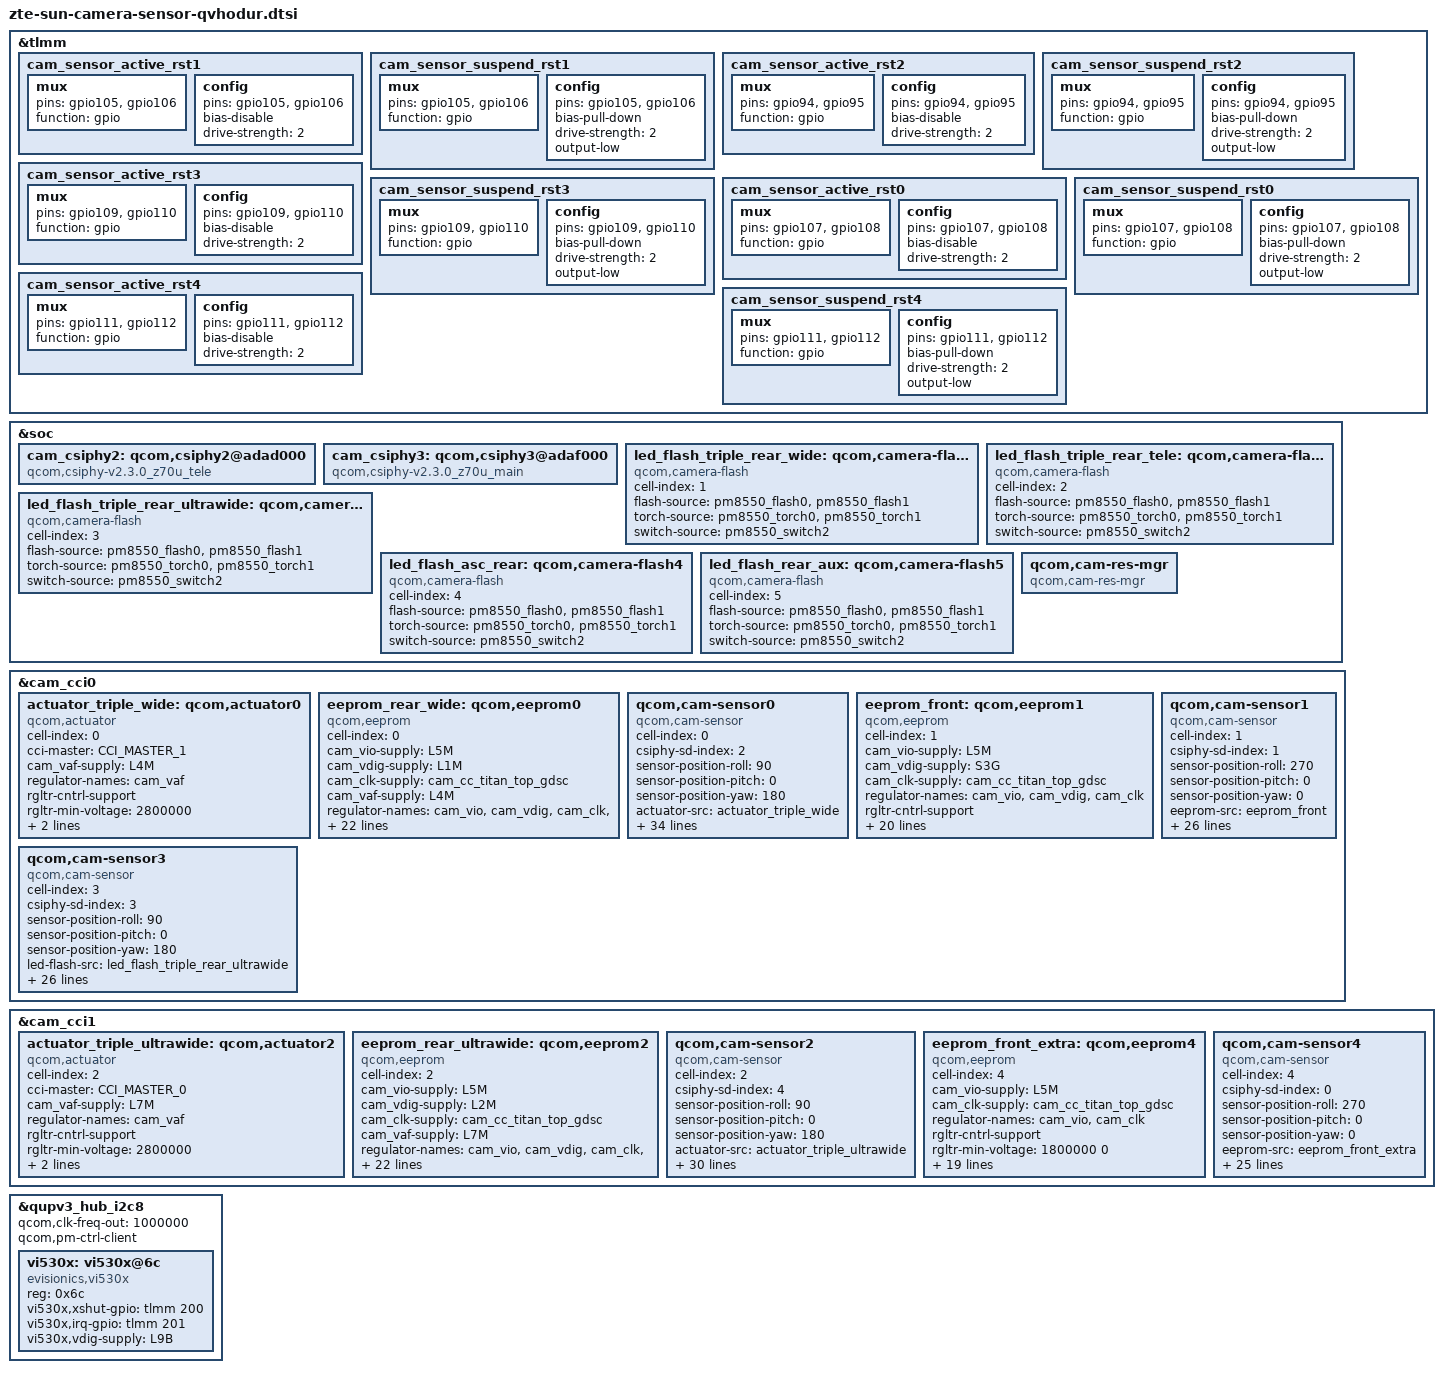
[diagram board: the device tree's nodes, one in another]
#include <dt-bindings/msm-camera.h>
&tlmm {
	cam_sensor_active_rst1: cam_sensor_active_rst1 {
		mux {
			pins = "gpio105", "gpio106";
			function = "gpio";
		};

		config {
			pins = "gpio105", "gpio106";
			bias-disable; /* No PULL */
			drive-strength = <2>; /* 2 MA */
		};
	};

	cam_sensor_suspend_rst1: cam_sensor_suspend_rst1 {
		mux {
			pins = "gpio105", "gpio106";
			function = "gpio";
		};

		config {
			pins = "gpio105", "gpio106";
			bias-pull-down; /* PULL DOWN */
			drive-strength = <2>; /* 2 MA */
			output-low;
		};
	};

	cam_sensor_active_rst2: cam_sensor_active_rst2 {
		mux {
			pins = "gpio94", "gpio95";
			function = "gpio";
		};

		config {
			pins = "gpio94", "gpio95";
			bias-disable; /* No PULL */
			drive-strength = <2>; /* 2 MA */
		};
	};

	cam_sensor_suspend_rst2: cam_sensor_suspend_rst2 {
		mux {
			pins = "gpio94", "gpio95";
			function = "gpio";
		};

		config {
			pins = "gpio94", "gpio95";
			bias-pull-down; /* PULL DOWN */
			drive-strength = <2>; /* 2 MA */
			output-low;
		};
	};

	cam_sensor_active_rst3: cam_sensor_active_rst3 {
		mux {
			pins = "gpio109", "gpio110";
			function = "gpio";
		};

		config {
			pins = "gpio109", "gpio110";
			bias-disable; /* No PULL */
			drive-strength = <2>; /* 2 MA */
		};
	};

	cam_sensor_suspend_rst3: cam_sensor_suspend_rst3 {
		mux {
			pins = "gpio109", "gpio110";
			function = "gpio";
		};

		config {
			pins = "gpio109", "gpio110";
			bias-pull-down; /* PULL DOWN */
			drive-strength = <2>; /* 2 MA */
			output-low;
		};
	};

	cam_sensor_active_rst0: cam_sensor_active_rst0 {
		mux {
			pins = "gpio107", "gpio108";
			function = "gpio";
		};

		config {
			pins = "gpio107", "gpio108";
			bias-disable; /* No PULL */
			drive-strength = <2>; /* 2 MA */
		};
	};

	cam_sensor_suspend_rst0: cam_sensor_suspend_rst0 {
		mux {
			pins = "gpio107", "gpio108";
			function = "gpio";
		};

		config {
			pins = "gpio107", "gpio108";
			bias-pull-down; /* PULL DOWN */
			drive-strength = <2>; /* 2 MA */
			output-low;
		};
	};

	cam_sensor_active_rst4: cam_sensor_active_rst4 {
		mux {
			pins = "gpio111", "gpio112";
			function = "gpio";
		};

		config {
			pins = "gpio111", "gpio112";
			bias-disable; /* No PULL */
			drive-strength = <2>; /* 2 MA */
		};
	};

	cam_sensor_suspend_rst4: cam_sensor_suspend_rst4 {
		mux {
			pins = "gpio111", "gpio112";
			function = "gpio";
		};

		config {
			pins = "gpio111", "gpio112";
			bias-pull-down; /* PULL DOWN */
			drive-strength = <2>; /* 2 MA */
			output-low;
		};
	};

};

&soc {
	cam_csiphy2: qcom,csiphy2@adad000 {
		compatible = "qcom,csiphy-v2.3.0_z70u_tele", "qcom,csiphy";
	};

	cam_csiphy3: qcom,csiphy3@adaf000 {
		compatible = "qcom,csiphy-v2.3.0_z70u_main", "qcom,csiphy";
	};

	led_flash_triple_rear_wide: qcom,camera-flash1 {
		cell-index = <1>;
		compatible = "qcom,camera-flash";
		flash-source = <&pm8550_flash0 &pm8550_flash1>;
		torch-source = <&pm8550_torch0 &pm8550_torch1>;
		switch-source = <&pm8550_switch2>;
		status = "ok";
	};

	led_flash_triple_rear_tele: qcom,camera-flash2 {
		cell-index = <2>;
		compatible = "qcom,camera-flash";
		flash-source = <&pm8550_flash0 &pm8550_flash1>;
		torch-source = <&pm8550_torch0 &pm8550_torch1>;
		switch-source = <&pm8550_switch2>;
		status = "ok";
	};

	led_flash_triple_rear_ultrawide: qcom,camera-flash3 {
		cell-index = <3>;
		compatible = "qcom,camera-flash";
		flash-source = <&pm8550_flash0 &pm8550_flash1>;
		torch-source = <&pm8550_torch0 &pm8550_torch1>;
		switch-source = <&pm8550_switch2>;
		status = "ok";
	};

	led_flash_asc_rear: qcom,camera-flash4 {
		cell-index = <4>;
		compatible = "qcom,camera-flash";
		flash-source = <&pm8550_flash0 &pm8550_flash1>;
		torch-source = <&pm8550_torch0 &pm8550_torch1>;
		switch-source = <&pm8550_switch2>;
		status = "ok";
	};

	led_flash_rear_aux: qcom,camera-flash5 {
		cell-index = <5>;
		compatible = "qcom,camera-flash";
		flash-source = <&pm8550_flash0 &pm8550_flash1>;
		torch-source = <&pm8550_torch0 &pm8550_torch1>;
		switch-source = <&pm8550_switch2>;
		status = "ok";
	};

	qcom,cam-res-mgr {
		compatible = "qcom,cam-res-mgr";
		status = "ok";
	};
};

&cam_cci0 {
	actuator_triple_wide: qcom,actuator0 {
		cell-index = <0>;
		compatible = "qcom,actuator";
		cci-master = <CCI_MASTER_1>;
		cam_vaf-supply = <&L4M>;
		regulator-names = "cam_vaf";
		rgltr-cntrl-support;
		rgltr-min-voltage = <2800000>;
		rgltr-max-voltage = <2800000>;
		rgltr-load-current = <67700>;
	};

	eeprom_rear_wide: qcom,eeprom0 {
		cell-index = <0>;
		compatible = "qcom,eeprom";
		cam_vio-supply = <&L5M>;
		cam_vdig-supply = <&L1M>;
		cam_clk-supply = <&cam_cc_titan_top_gdsc>;
		cam_vaf-supply = <&L4M>;
		regulator-names = "cam_vio", "cam_vdig", "cam_clk", "cam_vaf";
		rgltr-cntrl-support;
		rgltr-min-voltage = <1800000 1104000 0 2800000>;
		rgltr-max-voltage = <1800000 1104000 0 2800000>;
		rgltr-load-current = <155000 680000 0 67700>;
		gpio-no-mux = <0>;
		pinctrl-names = "cam_default", "cam_suspend";
		pinctrl-0 = <&cam_sensor_mclk1_active
				 &cam_sensor_active_rst1>;
		pinctrl-1 = <&cam_sensor_mclk1_suspend
				 &cam_sensor_suspend_rst1>;
		gpios = <&tlmm 90 0>,
			<&tlmm 105 0>,
			<&tlmm 106 0>;
		gpio-reset = <1>;
		gpio-custom1 = <2>;
		gpio-req-tbl-num = <0 1 2>;
		gpio-req-tbl-flags = <1 0 0>;
		gpio-req-tbl-label = "CAMIF_MCLK1",
					"CAM_RESET1",
					"CAM_VANA1";
		cci-master = <CCI_MASTER_1>;
		clocks = <&cambistmclkcc CAM_BIST_MCLK_CC_MCLK1_CLK>;
		clock-names = "cam_clk";
		clock-cntl-level = "nominal";
		clock-rates = <24000000>;
		status = "ok";
	};

	qcom,cam-sensor0 {
		cell-index = <0>;
		compatible = "qcom,cam-sensor";
		csiphy-sd-index = <2>;
		sensor-position-roll = <90>;
		sensor-position-pitch = <0>;
		sensor-position-yaw = <180>;
		actuator-src = <&actuator_triple_wide>;
		led-flash-src = <&led_flash_triple_rear_wide>;
		eeprom-src = <&eeprom_rear_wide>;
		cam_vio-supply = <&L5M>;
		cam_vdig-supply = <&L1M>;
		cam_clk-supply = <&cam_cc_titan_top_gdsc>;
		cam_vaf-supply = <&L4M>;
		cam_v_custom1-supply = <&L6M>;
		regulator-names = "cam_vio", "cam_vdig", "cam_clk", "cam_vaf", "cam_v_custom1";
		rgltr-cntrl-support;
		rgltr-min-voltage = <1800000 1104000 0 2800000 2800000>;
		rgltr-max-voltage = <1800000 1104000 0 2800000 2800000>;
		rgltr-load-current = <155000 680000 0 67700 67700>;
		gpio-no-mux = <0>;
		pinctrl-names = "cam_default", "cam_suspend";
		pinctrl-0 = <&cam_sensor_mclk1_active
				 &cam_sensor_active_rst1>;
		pinctrl-1 = <&cam_sensor_mclk1_suspend
				 &cam_sensor_suspend_rst1>;
		gpios = <&tlmm 90 0>,
			<&tlmm 105 0>,
			<&tlmm 106 0>;
		gpio-reset = <1>;
		gpio-custom1 = <2>;
		gpio-req-tbl-num = <0 1 2>;
		gpio-req-tbl-flags = <1 0 0>;
		gpio-req-tbl-label = "CAMIF_MCLK1",
					"CAM_RESET1",
					"CAM_VANA1";
		cci-master = <CCI_MASTER_1>;
		clocks = <&cambistmclkcc CAM_BIST_MCLK_CC_MCLK1_CLK>;
		clock-names = "cam_clk";
		clock-cntl-level = "nominal";
		clock-rates = <24000000>;
		status = "ok";
		zte-tof-enable;
	};

	eeprom_front: qcom,eeprom1 {
		cell-index = <1>;
		compatible = "qcom,eeprom";
		cam_vio-supply = <&L5M>;
		cam_vdig-supply = <&S3G>;
		cam_clk-supply = <&cam_cc_titan_top_gdsc>;
		regulator-names = "cam_vio", "cam_vdig", "cam_clk";
		rgltr-cntrl-support;
		rgltr-min-voltage = <1800000 1856000 0>;
		rgltr-max-voltage = <1800000 2000000 0>;
		rgltr-load-current = <4000 4000 0>;
		gpio-no-mux = <0>;
		pinctrl-names = "cam_default", "cam_suspend";
		pinctrl-0 = <&cam_sensor_mclk0_active
				 &cam_sensor_active_rst0>;
		pinctrl-1 = <&cam_sensor_mclk0_suspend
				 &cam_sensor_suspend_rst0>;
		gpios = <&tlmm 89 0>,
			<&tlmm 107 0>,
			<&tlmm 108 0>;
		gpio-reset = <1>;
		gpio-custom1 = <2>;
		gpio-req-tbl-num = <0 1 2>;
		gpio-req-tbl-flags = <1 0 0>;
		gpio-req-tbl-label = "CAMIF_MCLK0",
					"CAM_RESET0",
					"CAM_VANA0";
		cci-master = <CCI_MASTER_0>;
		clocks = <&cambistmclkcc CAM_BIST_MCLK_CC_MCLK0_CLK>;
		clock-names = "cam_clk";
		clock-cntl-level = "nominal";
		clock-rates = <24000000>;
		status = "ok";
	};

	qcom,cam-sensor1 {
		cell-index = <1>;
		compatible = "qcom,cam-sensor";
		csiphy-sd-index = <1>;
		sensor-position-roll = <270>;
		sensor-position-pitch = <0>;
		sensor-position-yaw = <0>;
		eeprom-src = <&eeprom_front>;
		cam_vio-supply = <&L5M>;
		cam_vdig-supply = <&S3G>;
		cam_clk-supply = <&cam_cc_titan_top_gdsc>;
		regulator-names = "cam_vio", "cam_vdig", "cam_clk";
		rgltr-cntrl-support;
		rgltr-min-voltage = <1800000 1856000 0>;
		rgltr-max-voltage = <1800000 2000000 0>;
		rgltr-load-current = <4000 4000 0>;
		gpio-no-mux = <0>;
		pinctrl-names = "cam_default", "cam_suspend";
		pinctrl-0 = <&cam_sensor_mclk0_active
				 &cam_sensor_active_rst0>;
		pinctrl-1 = <&cam_sensor_mclk0_suspend
				 &cam_sensor_suspend_rst0>;
		gpios = <&tlmm 89 0>,
			<&tlmm 107 0>,
			<&tlmm 108 0>;
		gpio-reset = <1>;
		gpio-custom1 = <2>;
		gpio-req-tbl-num = <0 1 2>;
		gpio-req-tbl-flags = <1 0 0>;
		gpio-req-tbl-label = "CAMIF_MCLK0",
					"CAM_RESET0",
					"CAM_VANA0";
		cci-master = <CCI_MASTER_0>;
		clocks = <&cambistmclkcc CAM_BIST_MCLK_CC_MCLK0_CLK>;
		clock-names = "cam_clk";
		clock-cntl-level = "nominal";
		clock-rates = <24000000>;
		status = "ok";
		zte-tof-enable;
	};

	qcom,cam-sensor3 {
		cell-index = <3>;
		compatible = "qcom,cam-sensor";
		csiphy-sd-index = <3>;
		sensor-position-roll = <90>;
		sensor-position-pitch = <0>;
		sensor-position-yaw = <180>;
		led-flash-src = <&led_flash_triple_rear_ultrawide>;
		cam_vio-supply = <&L5M>;
		cam_vdig-supply = <&S3G>;
		cam_clk-supply = <&cam_cc_titan_top_gdsc>;
		regulator-names = "cam_vio", "cam_vdig", "cam_clk";
		rgltr-cntrl-support;
		rgltr-min-voltage = <1800000 1856000 0>;
		rgltr-max-voltage = <1800000 2000000 0>;
		rgltr-load-current = <4000 4000 0>;
		gpio-no-mux = <0>;
		pinctrl-names = "cam_default", "cam_suspend";
		pinctrl-0 = <&cam_sensor_mclk3_active
				 &cam_sensor_active_rst3>;
		pinctrl-1 = <&cam_sensor_mclk3_suspend
				 &cam_sensor_suspend_rst3>;
		gpios = <&tlmm 92 0>,
			<&tlmm 109 0>,
			<&tlmm 110 0>;
		gpio-reset = <1>;
		gpio-custom1 = <2>;
		gpio-req-tbl-num = <0 1 2>;
		gpio-req-tbl-flags = <1 0 0>;
		gpio-req-tbl-label = "CAMIF_MCLK3",
					"CAM_RESET3",
					"CAM_VANA3";
		cci-master = <CCI_MASTER_0>;
		clocks = <&cambistmclkcc CAM_BIST_MCLK_CC_MCLK3_CLK>;
		clock-names = "cam_clk";
		clock-cntl-level = "nominal";
		clock-rates = <24000000>;
		status = "ok";
		zte-tof-enable;
	};

};

&cam_cci1 {
	actuator_triple_ultrawide: qcom,actuator2 {
		cell-index = <2>;
		compatible = "qcom,actuator";
		cci-master = <CCI_MASTER_0>;
		cam_vaf-supply = <&L7M>;
		regulator-names = "cam_vaf";
		rgltr-cntrl-support;
		rgltr-min-voltage = <2800000>;
		rgltr-max-voltage = <2800000>;
		rgltr-load-current = <119000>;
	};

	eeprom_rear_ultrawide: qcom,eeprom2 {
		cell-index = <2>;
		compatible = "qcom,eeprom";
		cam_vio-supply = <&L5M>;
		cam_vdig-supply = <&L2M>;
		cam_clk-supply = <&cam_cc_titan_top_gdsc>;
		cam_vaf-supply = <&L7M>;
		regulator-names = "cam_vio", "cam_vdig", "cam_clk", "cam_vaf";
		rgltr-cntrl-support;
		rgltr-min-voltage = <1800000 1100000 0 2800000>;
		rgltr-max-voltage = <1800000 1100000 0 2800000>;
		rgltr-load-current = <4000 155000 0 119000>;
		gpio-no-mux = <0>;
		pinctrl-names = "cam_default", "cam_suspend";
		pinctrl-0 = <&cam_sensor_mclk2_active
				 &cam_sensor_active_rst2>;
		pinctrl-1 = <&cam_sensor_mclk2_suspend
				 &cam_sensor_suspend_rst2>;
		gpios = <&tlmm 91 0>,
			<&tlmm 94 0>,
			<&tlmm 95 0>;
		gpio-reset = <1>;
		gpio-custom1 = <2>;
		gpio-req-tbl-num = <0 1 2>;
		gpio-req-tbl-flags = <1 0 0>;
		gpio-req-tbl-label = "CAMIF_MCLK2",
					"CAM_RESET2",
					"CAM_VANA2";
		cci-master = <CCI_MASTER_0>;
		clocks = <&cambistmclkcc CAM_BIST_MCLK_CC_MCLK2_CLK>;
		clock-names = "cam_clk";
		clock-cntl-level = "nominal";
		clock-rates = <24000000>;
		status = "ok";
	};

	qcom,cam-sensor2 {
		cell-index = <2>;
		compatible = "qcom,cam-sensor";
		csiphy-sd-index = <4>;
		sensor-position-roll = <90>;
		sensor-position-pitch = <0>;
		sensor-position-yaw = <180>;
		actuator-src = <&actuator_triple_ultrawide>;
		led-flash-src = <&led_flash_triple_rear_ultrawide>;
		eeprom-src = <&eeprom_rear_ultrawide>;
		cam_vio-supply = <&L5M>;
		cam_vdig-supply = <&L2M>;
		cam_clk-supply = <&cam_cc_titan_top_gdsc>;
		cam_vaf-supply = <&L7M>;
		regulator-names = "cam_vio", "cam_vdig", "cam_clk", "cam_vaf";
		rgltr-cntrl-support;
		rgltr-min-voltage = <1800000 1100000 0 2800000>;
		rgltr-max-voltage = <1800000 1100000 0 2800000>;
		rgltr-load-current = <4000 155000 0 119000>;
		gpio-no-mux = <0>;
		pinctrl-names = "cam_default", "cam_suspend";
		pinctrl-0 = <&cam_sensor_mclk2_active
				 &cam_sensor_active_rst2>;
		pinctrl-1 = <&cam_sensor_mclk2_suspend
				 &cam_sensor_suspend_rst2>;
		gpios = <&tlmm 91 0>,
			<&tlmm 94 0>,
			<&tlmm 95 0>;
		gpio-reset = <1>;
		gpio-custom1 = <2>;
		gpio-req-tbl-num = <0 1 2>;
		gpio-req-tbl-flags = <1 0 0>;
		gpio-req-tbl-label = "CAMIF_MCLK2",
					"CAM_RESET2",
					"CAM_VANA2";
		cci-master = <CCI_MASTER_0>;
		clocks = <&cambistmclkcc CAM_BIST_MCLK_CC_MCLK2_CLK>;
		clock-names = "cam_clk";
		clock-cntl-level = "nominal";
		clock-rates = <24000000>;
		status = "ok";
		zte-tof-enable;
	};

	eeprom_front_extra: qcom,eeprom4 {
		cell-index = <4>;
		compatible = "qcom,eeprom";
		cam_vio-supply = <&L5M>;
		cam_clk-supply = <&cam_cc_titan_top_gdsc>;
		regulator-names = "cam_vio", "cam_clk";
		rgltr-cntrl-support;
		rgltr-min-voltage = <1800000 0>;
		rgltr-max-voltage = <1800000 0>;
		rgltr-load-current = <4000 0>;
		gpio-no-mux = <0>;
		pinctrl-names = "cam_default", "cam_suspend";
		pinctrl-0 = <&cam_sensor_mclk4_active
				 &cam_sensor_active_rst4>;
		pinctrl-1 = <&cam_sensor_mclk4_suspend
				 &cam_sensor_suspend_rst4>;
		gpios = <&tlmm 93 0>,
			<&tlmm 111 0>,
			<&tlmm 112 0>;
		gpio-reset = <1>;
		gpio-custom1 = <2>;
		gpio-req-tbl-num = <0 1 2>;
		gpio-req-tbl-flags = <1 0 0>;
		gpio-req-tbl-label = "CAMIF_MCLK4",
					"CAM_RESET4",
					"CAM_VANA4";
		cci-master = <CCI_MASTER_0>;
		clocks = <&cambistmclkcc CAM_BIST_MCLK_CC_MCLK4_CLK>;
		clock-names = "cam_clk";
		clock-cntl-level = "nominal";
		clock-rates = <24000000>;
		status = "ok";
	};

	qcom,cam-sensor4 {
		cell-index = <4>;
		compatible = "qcom,cam-sensor";
		csiphy-sd-index = <0>;
		sensor-position-roll = <270>;
		sensor-position-pitch = <0>;
		sensor-position-yaw = <0>;
		eeprom-src = <&eeprom_front_extra>;
		cam_vio-supply = <&BOB1>;
		cam_clk-supply = <&cam_cc_titan_top_gdsc>;
		regulator-names = "cam_vio", "cam_clk";
		rgltr-cntrl-support;
		rgltr-min-voltage = <3008000 0>;
		rgltr-max-voltage = <4000000 0>;
		rgltr-load-current = <4000 0>;
		gpio-no-mux = <0>;
		pinctrl-names = "cam_default", "cam_suspend";
		pinctrl-0 = <&cam_sensor_mclk4_active
				 &cam_sensor_active_rst4>;
		pinctrl-1 = <&cam_sensor_mclk4_suspend
				 &cam_sensor_suspend_rst4>;
		gpios = <&tlmm 93 0>,
			<&tlmm 111 0>,
			<&tlmm 112 0>;
		gpio-reset = <1>;
		gpio-custom1 = <2>;
		gpio-req-tbl-num = <0 1 2>;
		gpio-req-tbl-flags = <1 0 0>;
		gpio-req-tbl-label = "CAMIF_MCLK4",
					"CAM_RESET4",
					"CAM_VANA4";
		cci-master = <CCI_MASTER_0>;
		clocks = <&cambistmclkcc CAM_BIST_MCLK_CC_MCLK4_CLK>;
		clock-names = "cam_clk";
		clock-cntl-level = "nominal";
		clock-rates = <24000000>;
		status = "ok";
		zte-tof-enable;
	};

};

&qupv3_hub_i2c8 {
	status = "ok";
	qcom,clk-freq-out = <1000000>;
	qcom,pm-ctrl-client;
	vi530x: vi530x@6c{
		reg = <0x6c>;
		compatible = "evisionics,vi530x";
		vi530x,xshut-gpio = <&tlmm 200 0>;  //RESET
		vi530x,irq-gpio = <&tlmm 201 0>;    //INT
		vi530x,vdig-supply = <&L9B>;   //VDD
		status = "ok";
	};
};
